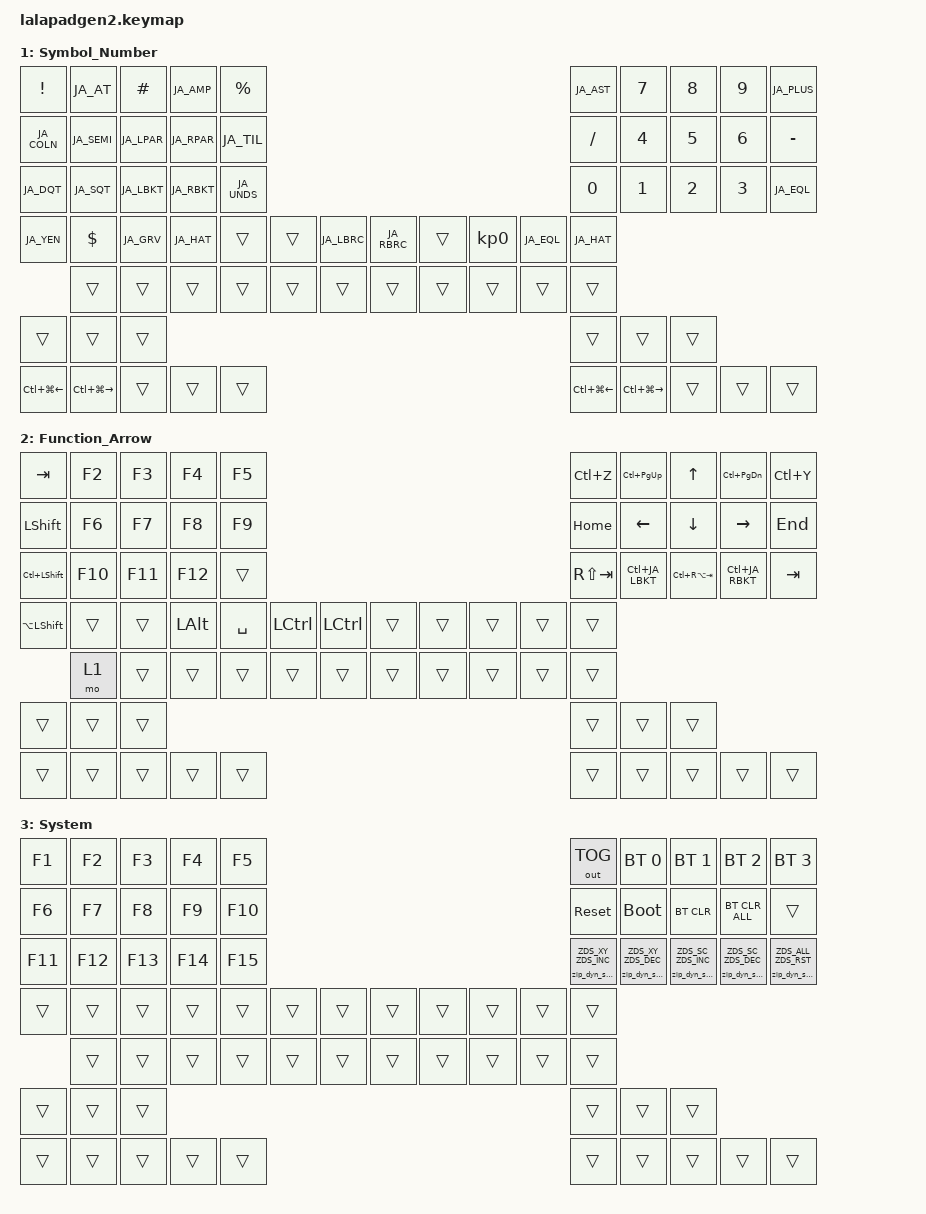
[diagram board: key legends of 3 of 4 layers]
#include <input/processors.dtsi>
#include <dt-bindings/zmk/zip_dynamic_scale.h>
#include <behaviors.dtsi>
#include <dt-bindings/zmk/bt.h>
#include <dt-bindings/zmk/keys.h>
#include <dt-bindings/zmk/outputs.h>
#include <dt-bindings/zmk/pointing.h>

#define DEFAULT 0
#define SYMBOL_NUMBER 1
#define FUNCTION_ARROW 2
#define SYSTEM 3

// --- JIS配列完全対応：記号スキャンコード再定義（Additive Only） ---
#define JA_AT   LBKT            // @
#define JA_HAT  EQUAL           // ^
#define JA_YEN  INT3            // ¥
#define JA_DQT  LS(N2)          // "
#define JA_AMP  LS(N6)          // &
#define JA_SQT  LS(N7)          // '
#define JA_LPAR LS(N8)          // (
#define JA_RPAR LS(N9)          // )
#define JA_EQL  LS(MINUS)       // =
#define JA_TIL  LS(JA_HAT)      // ~
#define JA_PIPE LS(INT3)        // |
#define JA_PLUS LS(SEMICOLON)   // +
#define JA_COLN SQT             // :
#define JA_AST  LS(SQT)         // *
#define JA_LBKT RBKT            // [
#define JA_RBKT NON_US_HASH     // ]
#define JA_LBRC LS(JA_LBKT)     // {
#define JA_RBRC LS(JA_RBKT)     // }
#define JA_UNDS LS(INT1)        // _ (ろキーにShiftを当てることでアンダーバーに固定)
#define JA_GRV  LS(JA_AT)       // ` (JIS配列ではShift + @ がバッククォート)
#define JA_SEMI SEMICOLON       // ;

&mt { quick-tap-ms = <200>; };

&lt { quick-tap-ms = <200>; };

/ {
    behaviors {
        zip_dyn_scale: zip_dyn_scale {
            compatible = "zmk,behavior-zip-dynamic-scale";
            #binding-cells = <2>;
        };

        zip_dyn_scale_set: zip_dyn_scale_set {
            compatible = "zmk,behavior-zip-dynamic-scale-set";
            #binding-cells = <2>;
        };

        mt2: mod_tap2 {
            compatible = "zmk,behavior-hold-tap";
            #binding-cells = <2>;
            flavor = "tap-preferred";
            tapping-term-ms = <150>;
            quick-tap-ms = <150>;
            require-prior-idle-ms = <125>;
            bindings = <&kp>, <&kp>;
        };

        tap_dance_layer_1and2: tap_dance_layer_1and2 {
            compatible = "zmk,behavior-tap-dance";
            label = "td_mo12";
            #binding-cells = <0>;
            bindings = <&mo 1>, <&mo 2>;
        };
    };

    combos {
        compatible = "zmk,combos";

        COMBO_TAB {
            bindings = <&kp TAB>;
            key-positions = <0 1>;
        };

        // O(8) と P(9) の同時押しで Delete
        combo_delete {
            timeout-ms = <50>;
            key-positions = <8 9>;
            bindings = <&kp DELETE>;
        };
    };

    keymap {
        compatible = "zmk,keymap";

        DEFAULT {
            display-name = "Default";
            bindings = <
&kp Q              &kp W      &kp E         &kp R        &kp T                                                                                                       &kp Y      &kp U      &kp I           &kp O           &kp P
&mt2 LEFT_SHIFT A  &kp S      &kp D         &kp F        &kp G                                                                                                       &kp H      &kp J      &kp K           &kp L           &mt2 RIGHT_SHIFT MINUS
&mt2 LC(LSHIFT) Z  &kp X      &kp C         &kp V        &kp B                                                                                                       &kp N      &kp M      &kp COMMA       &kp PERIOD      &mt2 LC(LSHIFT) SLASH
&kp LA(LSHIFT)     &kp LCTRL  &kp LEFT_WIN  &kp LEFT_ALT &lt 1 SPACE  &mt2 LCTRL GRAVE  &mkp LCLK  &lt 2 ENTER &mt2 LCTRL BACKSPACE &mo 2        &kp LANGUAGE_1  &mt2 LA(LSHIFT) ESCAPE
                   &kp LC(W) &kp LC(PAGE_DOWN)     &kp LA(LEFT)     &kp LC(PAGE_UP)     &kp LA(RIGHT)          &kp UP         &kp LEFT   &kp DOWN  &kp RIGHT       &none
&mkp LCLK          &mkp RCLK  &mkp MCLK                                                                                                                              &mkp LCLK       &mkp RCLK       &mkp MCLK
&mkp MB4           &mkp MB5   &kp LG(TAB)   &kp LG(D)    &kp LCTRL                                                                                                   &mkp MB4   &mkp MB5  &kp LG(TAB)     &kp LG(D)       &kp LCTRL
            >;
        };

        SYMBOL_NUMBER {
            display-name = "Symbol_Number";
            bindings = <
&kp EXCLAMATION  &kp JA_AT   &kp HASH     &kp JA_AMP   &kp PERCENT                                                                                                   &kp JA_AST       &kp N7            &kp N8          &kp N9          &kp JA_PLUS
&kp JA_COLN      &kp JA_SEMI &kp JA_LPAR  &kp JA_RPAR  &kp JA_TIL                                                                                                    &kp SLASH        &kp NUMBER_4      &kp N5          &kp NUMBER_6    &kp MINUS
&kp JA_DQT       &kp JA_SQT  &kp JA_LBKT  &kp JA_RBKT  &kp JA_UNDS                                                                                                   &kp N0           &kp NUMBER_1      &kp NUMBER_2    &kp NUMBER_3    &kp JA_EQL
&kp JA_YEN       &kp DOLLAR  &kp JA_GRV   &kp JA_HAT   &trans       &trans          &kp JA_LBRC  &kp JA_RBRC &trans             &kp KP_NUMBER_0   &kp JA_EQL      &kp JA_HAT
                 &trans      &trans       &trans       &trans       &trans          &trans       &trans      &trans      &trans           &trans            &trans
&trans           &trans      &trans                                                                                                                                  &trans            &trans          &trans
&kp LC(LG(LEFT)) &kp LC(LG(RIGHT)) &trans &trans       &trans                                                                                                      &kp LC(LG(LEFT)) &kp LC(LG(RIGHT)) &trans          &trans          &trans
            >;
        };

        FUNCTION_ARROW {
            display-name = "Function_Arrow";
            bindings = <
&kp TAB         &kp F2      &kp F3       &kp F4       &kp F5                                                                                                   &kp LC(Z)    &kp LC(PAGE_UP) &kp UP_ARROW  &kp LC(PAGE_DOWN) &kp LC(Y)
&kp LEFT_SHIFT  &kp F6      &kp F7       &kp F8       &kp F9                                                                                                   &kp HOME     &kp LEFT_ARROW  &kp DOWN_ARROW &kp RIGHT_ARROW  &kp END
&kp LC(LSHIFT)  &kp F10     &kp F11      &kp F12      &trans                                                                                                   &kp RS(TAB)  &kp LC(JA_LBKT) &kp LC(RA(TAB)) &kp LC(JA_RBKT) &kp TAB
&kp LA(LSHIFT)  &trans      &trans       &kp LEFT_ALT &kp SPACE    &kp LCTRL      &kp LCTRL      &trans     &trans       &trans          &trans        &trans
                &mo 1      &trans       &trans       &trans       &trans         &trans         &trans     &trans       &trans          &trans        &trans
&trans          &trans      &trans                                                                                                                         &trans          &trans        &trans
&trans          &trans      &trans       &trans       &trans                                                                                               &trans       &trans          &trans        &trans        &trans
            >;
        };

        SYSTEM {
            display-name = "System";
            bindings = <
&kp F1   &kp F2   &kp F3   &kp F4   &kp F5                     &out OUT_TOG                   &bt BT_SEL 0                   &bt BT_SEL 1                   &bt BT_SEL 2                   &bt BT_SEL 3
&kp F6   &kp F7   &kp F8   &kp F9   &kp F10                    &sys_reset                     &bootloader                    &bt BT_CLR                     &bt BT_CLR_ALL                 &trans
&kp F11  &kp F12  &kp F13  &kp F14  &kp F15                    &zip_dyn_scale ZDS_XY ZDS_INC  &zip_dyn_scale ZDS_XY ZDS_DEC  &zip_dyn_scale ZDS_SC ZDS_INC  &zip_dyn_scale ZDS_SC ZDS_DEC  &zip_dyn_scale ZDS_ALL ZDS_RST
&trans   &trans   &trans   &trans   &trans   &trans   &trans   &trans                         &trans                         &trans                         &trans                         &trans
         &trans   &trans   &trans   &trans   &trans   &trans   &trans                         &trans                         &trans                         &trans                         &trans
&trans   &trans   &trans                                                                                                                                    &trans                         &trans                         &trans
&trans   &trans   &trans   &trans   &trans                     &trans                         &trans                         &trans                         &trans                         &trans
            >;
        };
    };

    conditional_layers {
        compatible = "zmk,conditional-layers";

        Cond_Syslayer {
            if-layers = <1 2>;
            then-layer = <3>;
        };
    };
};
